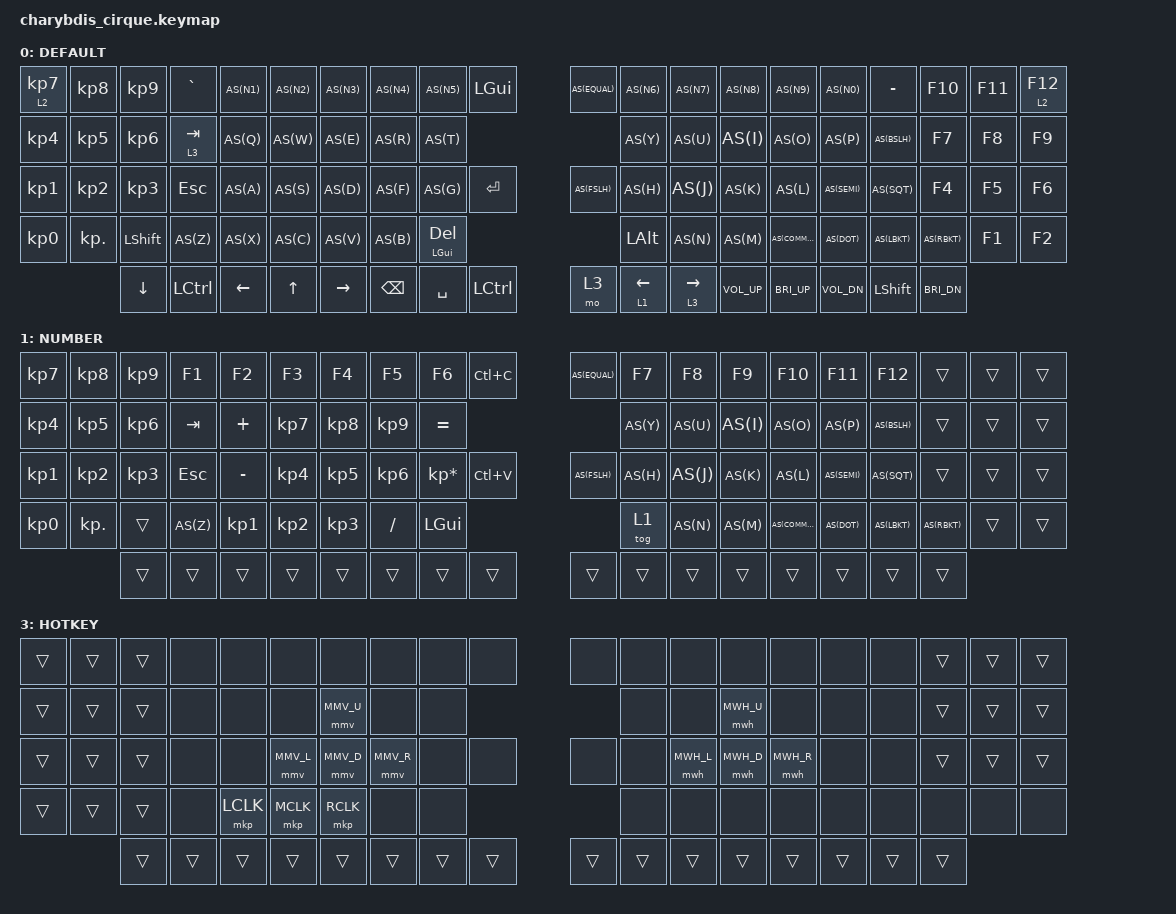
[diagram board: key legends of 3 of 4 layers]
#include <behaviors.dtsi>
#include <dt-bindings/zmk/mouse.h>
#include <dt-bindings/zmk/keys.h>
#include <dt-bindings/zmk/bt.h>
#include <dt-bindings/zmk/outputs.h>

// mouse move settings
#define MMV_U MOVE_VERT(-650)
#define MMV_D MOVE_VERT(650)
#define MMV_L MOVE_HOR(-650)
#define MMV_R MOVE_HOR(650)

&mmv {    
        time-to-max-speed-ms = <500>;
        acceleration-exponent=<1>;
};

// mouse wheel settings
#define MWH_U SCROLL_VERT(15)
#define MWH_D SCROLL_VERT(-15)
#define MWH_L SCROLL_HOR(-15)
#define MWH_R SCROLL_HOR(15)

&mwh {    
        time-to-max-speed-ms = <2000>;
        acceleration-exponent=<0>;
};

#define DEFAULT 0
#define NUMBER  1
#define SYMBOL  2
#define HOTKEY  3
#define MSE     4

#define AS(keycode) &as LS(keycode) keycode

/ {
        behaviors {
        td0: tap_dance_0 {
            compatible = "zmk,behavior-tap-dance";
            label = "TAP_DANCE_0";
            #binding-cells = <0>;
            tapping-term-ms = <200>;
            bindings = <&kp ESC>, <&kp TAB>;
        };
    };  

         behaviors {
       as: auto_shift {
        compatible = "zmk,behavior-hold-tap";
        label = "AUTO_SHIFT";
        #binding-cells = <2>;
        tapping-term-ms = <200>;
        quick-tap-ms = <0>;
        flavor = "tap-preferred";
        bindings = <&kp>, <&kp>;
                };             
modcp: mod_copy {
        compatible = "zmk,behavior-mod-morph";
        label = "MOD_COPY";
        #binding-cells = <0>;
        bindings = <&as LS(C) C>, <&kp C>;
        mods = <(LGUI | RGUI)>;
};
        };


    macros {
        macro_phone: macro_phone {
            // 1351
            label = "MACRO_PHONE";
            compatible = "zmk,behavior-macro";
            #binding-cells = <0>;
            bindings
                = < &kp N1 &kp N3 &kp N5  &kp N1>
                ;
        };
        macro_email_q: macro_email_q {
            // 2894512440@qq.com
            label = "MACRO_EMAIL_QQ";
            compatible = "zmk,behavior-macro";
            #binding-cells = <0>;
            bindings 
                = < &kp N2 &kp N8 &kp N9 &kp N4 &kp N5 &kp  N1 &kp N2 &kp N4 &kp N4 &kp N0 
                    &kp AT &kp Q &kp Q &kp DOT  &kp C &kp O &kp M>
                ;
        };
        macro_email_g: macro_email_g {
            // 135115
            compatible = "zmk,behavior-macro";
            label = "MACRO_EMAIL_GMAIL";
            #binding-cells = <0>;
            bindings
                = < &kp N1 &kp N3 &kp N5  &kp N1 &kp N1 &kp N5 > ;
        };
       
    };
    
     combos {
        compatible = "zmk,combos";

       
         combo_2 {
            timeout-ms = <50>;
            key-positions = <43 82>;
            bindings = <&kp N2 >;
        };
         combo_3 {
            timeout-ms = <50>;
            key-positions = <44 82>;
            bindings = <&kp N3>;
        };
            combo_LGUI {
            timeout-ms = <50>;
            key-positions = <45 82>;
            bindings = <&kp N4>;
        };
              combo_GUI {
            timeout-ms = <50>;
            key-positions = <62 82>;
            bindings = <&kp LGUI>;
        };
                  combo_G {
            timeout-ms = <50>;
            key-positions = <63 82>;
            bindings = <&tog 1>;
        };
                  combo_GU {
            timeout-ms = <50>;
            key-positions = <64 82>;
            bindings = <&mo 3>;
        };
             
  
   };



    keymap {
       compatible = "zmk,keymap";
       default_layer {
            label = "DEFAULT";
           bindings = <
   &lt 2 KP_N7 &kp KP_N8 &kp KP_N9 &kp GRAVE AS(N1) AS(N2) AS(N3) AS(N4) AS(N5) &kp LGUI   AS(EQUAL)AS(N6) AS(N7) AS(N8)  AS(N9) AS(N0) &kp MINUS &kp F10  &kp F11   &lt 2 F12 
   &kp KP_N4 &kp KP_N5 &kp KP_N6  &lt 3 TAB  AS(Q) AS(W) AS(E) AS(R) AS(T)                      AS(Y) AS(U) AS(I) AS(O) AS(P) AS(BSLH) &kp F7 &kp F8  &kp F9
   &kp KP_N1 &kp KP_N2 &kp KP_N3 &kp ESC  AS(A) AS(S) AS(D) AS(F) AS(G) &kp ENTER     AS(FSLH) AS(H)  AS(J) AS(K) AS(L) AS(SEMI) AS(SQT) &kp F4 &kp F5 &kp F6
   &kp KP_N0 &kp KP_DOT &kp LSHFT   AS(Z) AS(X) AS(C) AS(V) AS(B)  &mt LGUI DEL              &kp LALT AS(N) AS(M) AS(COMMA) AS(DOT) AS(LBKT) AS(RBKT)  &kp F1 &kp F2 
       &kp DOWN &kp LCTRL  &kp LEFT &kp UP &kp RIGHT &kp BSPC &kp SPACE &kp LCTRL                          &mo 3 &lt 1 LEFT &lt 3 RIGHT &kp C_VOL_UP  &kp C_BRI_UP &kp C_VOL_DN  &kp LSHFT &kp C_BRI_DN 
            >;
        };
            number_layer {
            label = "NUMBER";
            bindings = <
   &kp KP_N7 &kp KP_N8 &kp KP_N9   &kp F1 &kp F2 &kp F3 &kp F4 &kp F5  &kp F6 &kp LC(C)   AS(EQUAL) &kp F7 &kp F8 &kp F9 &kp F10     &kp F11   &kp F12  &trans &trans &trans  
     &kp KP_N4 &kp KP_N5 &kp KP_N6   &kp TAB  &kp PLUS &kp KP_N7 &kp KP_N8 &kp KP_N9  &kp EQUAL                      AS(Y) AS(U) AS(I) AS(O) AS(P) AS(BSLH)  &trans &trans &trans  
    &kp KP_N1 &kp KP_N2 &kp KP_N3   &kp ESC  &kp MINUS  &kp KP_N4 &kp KP_N5 &kp KP_N6  &kp KP_MULTIPLY &kp LC(V)       AS(FSLH) AS(H)  AS(J) AS(K) AS(L) AS(SEMI) AS(SQT)  &trans &trans &trans  
   &kp KP_N0 &kp KP_DOT          &trans   AS(Z) &kp KP_N1 &kp KP_N2 &kp KP_N3 &kp FSLH  &kp LGUI              &tog 1 AS(N) AS(M) AS(COMMA) AS(DOT) AS(LBKT) AS(RBKT)   &trans &trans  
         &trans  &trans  &trans   &trans  &trans  &trans   &trans  &trans                       &trans  &trans  &trans   &trans  &trans  &trans   &trans  &trans  
            >;
        };
                     
        symbol_layer {
            label = "SYMBOL";
            bindings = <
   &trans  &trans  &trans   &bt BT_SEL 0 &bt BT_SEL 1 &bt BT_SEL 2 &bt BT_SEL 3 &bt BT_SEL 4 &bt BT_CLR  &kp LC(C)   AS(EQUAL)  &bt BT_SEL 0 &bt BT_SEL 1 &bt BT_SEL 2 &bt BT_SEL 3 &bt BT_SEL 4 &bt BT_CLR  &trans &trans &trans
   &trans  &trans  &trans   &none &none &none &none       &none &out OUT_USB      &out OUT_USB &none &none &none       &none &none  &trans &trans &trans
 &trans  &trans  &trans  &none &none &none &none       &none &out OUT_BLE   &none       &none   &out OUT_BLE &none &none &none       &none &none    &none   &none &none  
    &trans &trans        &none     &none   &none   &none   &none   &none   &none              &none  &none   &none   &none   &none   &none   &none           &none   &none &none 
          &trans  &trans  &trans   &trans  &trans  &trans   &trans  &trans                    &trans  &trans  &trans   &trans  &trans  &trans   &trans  &trans  
            >;
        };


        hotkey_layer {
            label = "HOTKEY";
            bindings = <
&trans  &trans  &trans   &none &none &none &none       &none &none &none &none     &none &none &none &none      &none &none      &trans &trans &trans
   &trans  &trans  &trans   &none &none  &none       &mmv MMV_U  &none       &none                 &none  &none       &mwh MWH_U  &none       &none  &none  &trans &trans &trans
 &trans  &trans  &trans  &none &none &mmv MMV_L &mmv MMV_D &mmv MMV_R &none      &none          &none     &none  &mwh MWH_L  &mwh MWH_D  &mwh MWH_R  &none  &none &trans    &trans   &trans 
    &trans &trans        &trans   &none &mkp LCLK &mkp MCLK &mkp RCLK   &none &none &none &none      &none   &none   &none   &none           &none   &none &none 
          &trans  &trans  &trans   &trans  &trans  &trans   &trans  &trans                    &trans  &trans  &trans   &trans  &trans  &trans   &trans  &trans                                                    
            >;
        };
        
  
        
        
        
   };
};
